# STM32G070 register map
File version: 1.9
CPU: CM0 r0p1, little endian, MPU, no FPU, 2 interrupt priority bits
Registers are 32-bit, read-write, reset 0x0 unless marked. A register's access mark holds for its fields unless they carry their own. Offsets are from the block's base; [hi:lo] are bit positions; {n}, {i} and the like mark numbered series; 'fields as' and 'values as' point back to an identical list.

## EXTI — External interrupt/event controller
Base 0x40021800
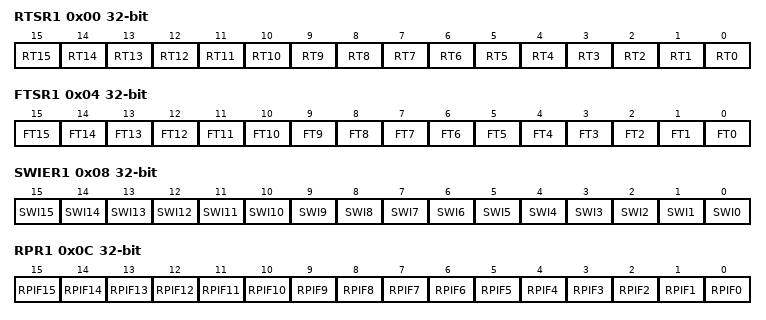
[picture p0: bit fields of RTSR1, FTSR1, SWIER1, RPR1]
0x00 RTSR1 — EXTI rising trigger selection register
  [all] fields
    0=Disabled (Rising edge trigger is disabled); 1=Enabled (Rising edge trigger is enabled)
  [n] RT{n} (n=0..15) — Rising trigger event configuration bit of Configurable Event line
0x04 FTSR1 — EXTI falling trigger selection register
  [all] fields
    0=Disabled (Falling edge trigger is disabled); 1=Enabled (Falling edge trigger is enabled)
  [n] FT{n} (n=0..15) — Falling trigger event configuration bit of configurable line
0x08 SWIER1 — EXTI software interrupt event register
  [all] fields
    on write: 1=Pend (Generates an interrupt request)
  [n] SWI{n} (n=0..15) — Software rising edge event trigger on line
0x0C RPR1 — EXTI rising edge pending register
  [all] fields
    on read: 0=NotPending (No trigger request occurred); 1=Pending (Selected trigger request occurred) | on write: 1=Clears pending bit
  [n] RPIF{n} write-1-clears (n=6..15) — Rising edge event pending for configurable line
  [5] RPIF5 write-1-clears — configurable event inputs x rising edge Pending bit
  [n] RPIF{n} write-1-clears (n=0..4) — Rising edge event pending for configurable line
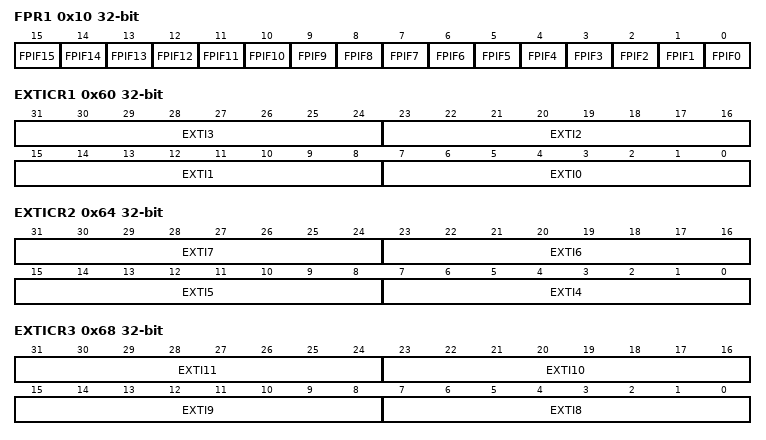
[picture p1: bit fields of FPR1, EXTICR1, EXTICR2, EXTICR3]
0x10 FPR1 — EXTI falling edge pending register
  [all] fields
    values as the fields of RPR1
  [n] FPIF{n} write-1-clears (n=0..15) — Falling edge event pending for configurable line
0x60 EXTICR1 — EXTI external interrupt selection register
  [all] fields
    0=PA (Select PAx as the source input for the EXTIx external interrupt); 1=PB (Select PBx as the source input for the EXTIx external interrupt); 2=PC (Select PCx as the source input for the EXTIx external interrupt); 3=PD (Select PDx as the source input for the EXTIx external interrupt); 5=PF (Select PFx as the source input for the EXTIx external interrupt)
  [8n+7:8n] EXTI{n} (n=0..3) — GPIO port selection
0x64 EXTICR2 — EXTI external interrupt selection register
  [all] fields
    values as the fields of EXTICR1
  [8n-25:8n-32] EXTI{n} (n=4..7) — GPIO port selection
0x68 EXTICR3 — EXTI external interrupt selection register
  [all] fields
    values as the fields of EXTICR1
  [8n-57:8n-64] EXTI{n} (n=8..11) — GPIO port selection
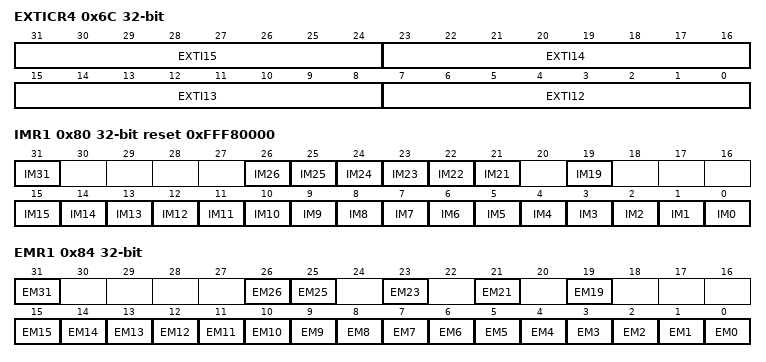
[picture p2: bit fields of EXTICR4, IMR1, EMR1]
0x6C EXTICR4 — EXTI external interrupt selection register
  [all] fields
    values as the fields of EXTICR1
  [8n-89:8n-96] EXTI{n} (n=12..15) — GPIO port selection
0x80 IMR1 reset 0xFFF80000 — EXTI CPU wakeup with interrupt mask register
  [all] fields
    0=Masked (Interrupt request line is masked); 1=Unmasked (Interrupt request line is unmasked)
  [31] IM31 — CPU wakeup with interrupt mask on event input
  [n] IM{n} (n=21..26) — CPU wakeup with interrupt mask on event input
  [19] IM19 — CPU wakeup with interrupt mask on event input
  [n] IM{n} (n=0..15) — CPU wakeup with interrupt mask on event input
0x84 EMR1 (alternate view of IMR1) — EXTI CPU wakeup with event mask register
  [all] fields
    0=Masked (Event request line is masked); 1=Unmasked (Event request line is unmasked)
  [31] EM31 — CPU wakeup with event mask on event input
  [26] EM26 — CPU wakeup with event mask on event input
  [25] EM25 — CPU wakeup with event mask on event input
  [23] EM23 — CPU wakeup with event mask on event input
  [21] EM21 — CPU wakeup with event mask on event input
  [19] EM19 — CPU wakeup with event mask on event input
  [n] EM{n} (n=0..15) — CPU wakeup with event mask on event input

## TIM6 — Basic timers
Base 0x40001000
Same registers: TIM7 0x40001400
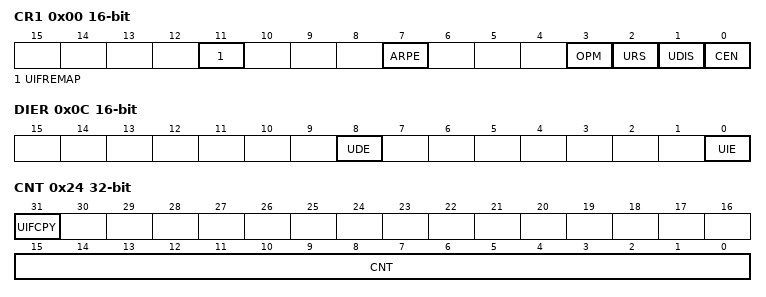
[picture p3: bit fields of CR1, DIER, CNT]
0x00 CR1 16-bit — control register 1
  [11] UIFREMAP — UIF status bit remapping
  [7] ARPE — Auto-reload preload enable
    0=Disabled (TIMx_APRR register is not buffered); 1=Enabled (TIMx_APRR register is buffered)
  [3] OPM — One-pulse mode
    0=Disabled (Counter is not stopped at update event); 1=Enabled (Counter stops counting at the next update event (clearing the CEN bit))
  [2] URS — Update request source
    0=AnyEvent (Any of counter overflow/underflow, setting UG, or update through slave mode, generates an update interrupt or DMA request); 1=CounterOnly (Only counter overflow/underflow generates an update interrupt or DMA request)
  [1] UDIS — Update disable
    0=Enabled (Update event enabled); 1=Disabled (Update event disabled)
  [0] CEN — Counter enable
    0=Disabled (Counter disabled); 1=Enabled (Counter enabled)
0x04 CR2 16-bit — control register 2
  [6:4] MMS — Master mode selection
    0=Reset (Use UG bit from TIMx_EGR register); 1=Enable (Use CNT bit from TIMx_CEN register); 2=Update (Use the update event)
0x0C DIER 16-bit — DMA/Interrupt enable register
  [8] UDE — Update DMA request enable
    0=Disabled (Update DMA request disabled); 1=Enabled (Update DMA request enabled)
  [0] UIE — Update interrupt enable
    0=Disabled (Update interrupt disabled); 1=Enabled (Update interrupt enabled)
0x10 SR 16-bit — status register
  [0] UIF write-0-clears — Update interrupt flag
    on read: 0=NoUpdateOccurred; 1=UpdatePending (Update interrupt pending) | on write: 0=Clear flag
0x14 EGR wo — event generation register
  [0] UG — Update generation
    1=Update (Re-initializes the timer counter and generates an update of the registers.)
0x24 CNT — counter
  [31] UIFCPY — UIF Copy
  [15:0] CNT — Low counter value
0x24 CNT16 16-bit (alternate view of CNT) — 16-bit counter register
  [15:0] CNT — counter value
0x28 PSC 16-bit — prescaler
  [15:0] PSC — Prescaler value
0x2C ARR 16-bit reset 0xFFFF — auto-reload register
  [15:0] ARR — Low Auto-reload value
